AUTOSAR XML (schema 00050)
package /Diag_RidSwc
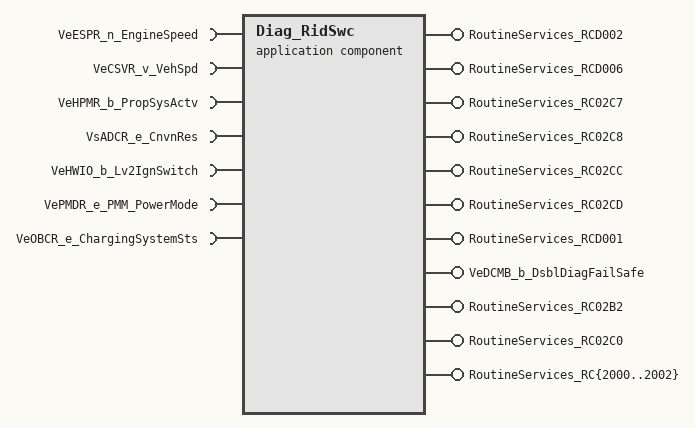
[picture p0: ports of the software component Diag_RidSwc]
  application sw component type Diag_RidSwc
    13 x provide port:
      RoutineServices_RCD002: provided-interface=RoutineServices_RCD002
      RoutineServices_RCD006: provided-interface=RoutineServices_RCD006
      RoutineServices_RC02C7: provided-interface=RoutineServices_RC02C7
      RoutineServices_RC02C8: provided-interface=RoutineServices_RC02C8
      RoutineServices_RC02CC: provided-interface=RoutineServices_RC02CC
      RoutineServices_RC02CD: provided-interface=RoutineServices_RC02CD
      RoutineServices_RCD001: provided-interface=RoutineServices_RCD001
      VeDCMB_b_DsblDiagFailSafe: provided-interface=VeDCMB_b_DsblDiagFailSafe
      RoutineServices_RC02B2: provided-interface=RoutineServices_RC02B2
      RoutineServices_RC02C0: provided-interface=RoutineServices_RC02C0
      RoutineServices_RC{2000..2002}: provided-interface=RoutineServices_RC{2000..2002}
    7 x require port:
      VeESPR_n_EngineSpeed: nonqueued-receiver-com-spec{data-element=Value, handle-never-received=true, init-value=0}, required-interface=VeESPR_n_EngineSpeed
      VeCSVR_v_VehSpd: nonqueued-receiver-com-spec{data-element=Value, handle-never-received=true, init-value=0}, required-interface=VeCSVR_v_VehSpd
      VeHPMR_b_PropSysActv: nonqueued-receiver-com-spec{data-element=Value, handle-never-received=true, init-value=0}, required-interface=VeHPMR_b_PropSysActv
      VsADCR_e_CnvnRes: required-interface=VsADCR_e_CnvnRes
      VeHWIO_b_Lv2IgnSwitch: nonqueued-receiver-com-spec{data-element=Value, handle-never-received=true, init-value=0}, required-interface=VeHWIO_b_Lv2IgnSwitch
      VePMDR_e_PMM_PowerMode: required-interface=VePMDR_e_PMM_PowerMode
      VeOBCR_e_ChargingSystemSts: required-interface=VeOBCR_e_ChargingSystemSts
    behavior SwcInternalBehavior_0: data-type-mapping=[ADTtoIDTMapping, ADTtoIDTMapping, ADTtoIDTMapping, msADTtoIDTMapping]
      15 x operation invoked event:
        Op_RID_D002_Start: start-on-event=RE_RID_D002_Start, operation=RoutineServices_RCD002.Start
        Op_RID_D001_Start: start-on-event=RE_RID_D001_Start, operation=RoutineServices_RCD001.Start
        Op_RID_D001_Stop: start-on-event=RE_RID_D001_Stop, operation=RoutineServices_RCD001.Stop
        Op_RE_RID_D006_Start: start-on-event=RE_RID_D006_Start, operation=RoutineServices_RCD006.Start
        Op_RE_RID_D006_ReqRslt: start-on-event=RE_RID_D006_ReqRslt, operation=RoutineServices_RCD006.RequestResults
        Op_RC02C7_LINECUParNum16: start-on-event=RE_RC02C7_LINECUParNum16_Start, operation=RoutineServices_RC02C7.Start
        Op_RC02C8_LINECUParNum_Start: start-on-event=RE_RC02C8_LINECUParNum_Start, operation=RoutineServices_RC02C8.Start
        Op_RC02CC_LINECUASCParNum_Start: start-on-event=RE_RC02CC_LINECUASCParNum_Start, operation=RoutineServices_RC02CC.Start
        Op_RC02CD_LINECUASCParNum_start: start-on-event=RE_RC02CD_LINECUASCParNum_start, operation=RoutineServices_RC02CD.Start
        Op_RID_RC02B2: start-on-event=RE_RID_RC02B2_Start, operation=RoutineServices_RC02B2.Start
        Op_RID_RC02C0_Start: start-on-event=RE_RID_RC02C0_Start, operation=RoutineServices_RC02C0.Start
        Op_RID_RC{2000..2002}_Start: start-on-event=RE_RID_RC{2000..2002}_Start, operation=RoutineServices_RC{2000..2002}.Start
        Op_RID_RC2002_ReqRslt: start-on-event=RE_RID_RC2002_Start_ReqRslt, operation=RoutineServices_RC2002.RequestResults
      15 x runnable:
        RE_RID_D001_Start: symbol=RE_RID_D001_Start_func
          data-send-points:
            access DSP_VeDCMB_b_DisblDiagFailSafe_0: accessed-variable=VeDCMB_b_DsblDiagFailSafe.VeDCMB_b_DsblDiagFailSafe
        RE_RID_D001_Stop: symbol=RE_RID_D001_Stop_func
          data-send-points:
            access DSP_VeDCMB_b_DisblDiagFailSafe_0: accessed-variable=VeDCMB_b_DsblDiagFailSafe.VeDCMB_b_DsblDiagFailSafe
        RE_RID_D002_Start: symbol=RE_RID_D002_Start_func
          data-receive-point-by-arguments:
            7 x access:
              DataReceivePointByArguments_VariableAccess_0: accessed-variable=VeESPR_n_EngineSpeed.Value
              DataReceivePointByArguments_VariableAccess_1: accessed-variable=VeCSVR_v_VehSpd.Value
              DataReceivePointByArguments_VariableAccess_2: accessed-variable=VeHPMR_b_PropSysActv.Value
              DataReceivePointByArguments_VariableAccess_3: accessed-variable=VsADCR_e_CnvnRes.VsADCR_e_CnvnRes
              DataReceivePointByArguments_VariableAccess_4: accessed-variable=VeHWIO_b_Lv2IgnSwitch.Value
              DataReceivePointByArguments_VariableAccess_5: accessed-variable=VePMDR_e_PMM_PowerMode.Value
              DataReceivePointByArguments_VariableAccess_6: accessed-variable=VeOBCR_e_ChargingSystemSts.Value
        RE_RID_D006_Start: symbol=RE_RID_D006_Start_func
        RE_RID_D006_ReqRslt: symbol=RE_RID_D006_ReqRslt_func
        RE_RC02C7_LINECUParNum16_Start: symbol=RE_RC02C7_LINECUParNum16_Startfunc
        RE_RC02C8_LINECUParNum_Start: symbol=RE_RC02C8_LINECUParNum_Start_func
        RE_RC02CC_LINECUASCParNum_Start: symbol=RE_RC02CC_LINECUASCParNum_Start_func
        RE_RC02CD_LINECUASCParNum_start: symbol=RE_RC02CD_LINECUASCParNum_start_func
        RE_RID_RC02B2_Start: symbol=RE_RID_RC02B2_Startfunc
        RE_RID_RC02C0_Start: symbol=RE_RID_RC02C0_Startfunc
        RE_RID_RC2000_Start
        RE_RID_RC2001_Start: symbol=RE_RID_RC2001_Startfunc
        RE_RID_RC2002_Start: symbol=RE_RID_RC2002_Startfunc
        RE_RID_RC2002_Start_ReqRslt: symbol=RE_RID_RC2002_Start_ReqRsltfunc
      shared-parameters:
        6 x parameter data prototype, all with sw-calibration-access=READ-ONLY, type=float32:
          KeDIAG_EngineSpeed: init-value=NumericalValueSpecification_0:20.0
          KeDIAG_VehicleSpeed: init-value=NumericalValueSpecification_0:20.0
          KeHWIO_PrgmCond_BattVoltLowLimTol: init-value=NumericalValueSpecification_0:0.5
          KeHWIO_PrgmCond_BattVoltHighLimTol: init-value=NumericalValueSpecification_0:0.80
          BATT_VOLT_OPER_LOWER_LIM: init-value=NumericalValueSpecification_0:9.0
          BATT_VOLT_OPER_HIGHER_LIM: init-value=NumericalValueSpecification_0:16.0
